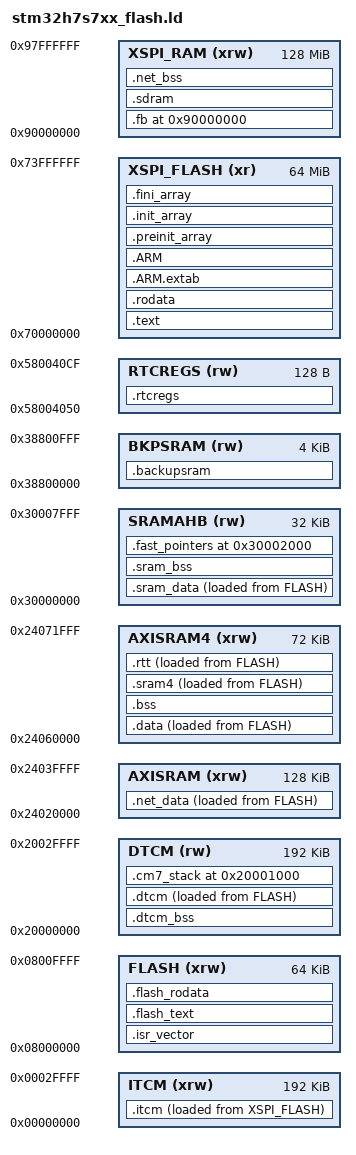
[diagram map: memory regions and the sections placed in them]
/*
******************************************************************************
**
** @file        : LinkerScript.ld
**
** @author      : Auto-generated by STM32CubeIDE
**
** @brief       : Linker script for STM32H7S7xx Device from STM32H7RS series
**                      64Kbytes FLASH
**                      456Kbytes RAM
**
**                Set heap size, stack size and stack location according
**                to application requirements.
**
**                Set memory bank area and size if external memory is used
**
**  Target      : STMicroelectronics STM32
**
**  Distribution: The file is distributed as is, without any warranty
**                of any kind.
**
******************************************************************************
** @attention
**
** Copyright (c) 2023 STMicroelectronics.
** All rights reserved.
**
** This software is licensed under terms that can be found in the LICENSE file
** in the root directory of this software component.
** If no LICENSE file comes with this software, it is provided AS-IS.
**
******************************************************************************
*/

/* Entry Point */
ENTRY(Reset_Handler)

_Min_Heap_Size = 0x200; /* required amount of heap */
_Min_Stack_Size = 0x400; /* required amount of stack */

__FLASH_BEGIN  = 0x08000000;
__FLASH_SIZE   = 0x00010000;

/* Memories definition */
MEMORY
{
  AXISRAM       (xrw) : ORIGIN = 0x24020000,    LENGTH = 0x20000
  AXISRAM4  (xrw) : ORIGIN = 0x24060000, LENGTH = 0x12000

  ITCM      (xrw) : ORIGIN = 0x00000000,    LENGTH = 0x00030000
  DTCM       (rw) : ORIGIN = 0x20000000,    LENGTH = 0x00030000
  SRAMAHB   (rw)  : ORIGIN = 0x30000000,  LENGTH = 0x00008000
  BKPSRAM   (rw)  : ORIGIN = 0x38800000,  LENGTH = 0x00001000

  FLASH     (xrw) : ORIGIN = __FLASH_BEGIN, LENGTH = __FLASH_SIZE

  XSPI_RAM  (xrw) : ORIGIN = 0x90000000, LENGTH = 0x08000000
  XSPI_FLASH (xr) : ORIGIN = 0x70000000, LENGTH = 0x04000000

  /* RTC backup registers */
  RTCREGS (rw)        : ORIGIN = 0x58004050, LENGTH = 128
}

/* Sections */
SECTIONS
{
  /* The startup code into "FLASH" Rom type memory */
  .isr_vector :
  {
    . = ALIGN(4);
    KEEP(*(.isr_vector)) /* Startup code */
    . = ALIGN(4);
  } >FLASH

  /* Startup code to bring the xspi interface online */
  .flash_text :
  {
    . = ALIGN(4);
    *(.flash_text)
    *(.flash_text*)
    *SEGGER_RTT*(.text)
    *SEGGER_RTT*(.text*)
    . = ALIGN(4);
  } >FLASH


  /* The program code and other data into "FLASH" Rom type memory */
  .text :
  {
    . = ALIGN(4);
    *(.text)           /* .text sections (code) */
    *(.text*)          /* .text* sections (code) */
    *(.glue_7)         /* glue arm to thumb code */
    *(.glue_7t)        /* glue thumb to arm code */
    *(.eh_frame)

    KEEP (*(.init))
    KEEP (*(.fini))

    . = ALIGN(4);
    _etext = .;        /* define a global symbols at end of code */
  } >XSPI_FLASH

  /* Boot-time constant data */
  .flash_rodata :
  {
    . = ALIGN(4);
    *(.flash_rodata)
    *(.flash_rodata*)
    *(.flash_string)
    *(.flash_string*)
    . = ALIGN(4);
  } >FLASH

  /* Constant data into "FLASH" Rom type memory */
  .rodata :
  {
    . = ALIGN(4);
    *(.rodata)         /* .rodata sections (constants, strings, etc.) */
    *(.rodata*)        /* .rodata* sections (constants, strings, etc.) */
    . = ALIGN(4);
  } >XSPI_FLASH

  .ARM.extab (READONLY) : /* The READONLY keyword is only supported in GCC11 and later, remove it if using GCC10 or earlier. */
  {
    . = ALIGN(4);
    *(.ARM.extab* .gnu.linkonce.armextab.*)
    . = ALIGN(4);
  } >XSPI_FLASH

  .ARM (READONLY) : /* The READONLY keyword is only supported in GCC11 and later, remove it if using GCC10 or earlier. */
   {
    . = ALIGN(4);
    __exidx_start = .;
    *(.ARM.exidx*)
    __exidx_end = .;
    . = ALIGN(4);
  } >XSPI_FLASH

  .preinit_array  (READONLY) : /* The READONLY keyword is only supported in GCC11 and later, remove it if using GCC10 or earlier. */
  {
    . = ALIGN(4);
    PROVIDE_HIDDEN (__preinit_array_start = .);
    KEEP (*(.preinit_array*))
    PROVIDE_HIDDEN (__preinit_array_end = .);
    . = ALIGN(4);
  } >XSPI_FLASH

  .init_array (READONLY) : /* The READONLY keyword is only supported in GCC11 and later, remove it if using GCC10 or earlier. */
  {
    . = ALIGN(4);
    PROVIDE_HIDDEN (__init_array_start = .);
    KEEP (*(SORT(.init_array.*)))
    KEEP (*(.init_array*))
    PROVIDE_HIDDEN (__init_array_end = .);
    . = ALIGN(4);
  } >XSPI_FLASH

  .fini_array (READONLY) : /* The READONLY keyword is only supported in GCC11 and later, remove it if using GCC10 or earlier. */
  {
    . = ALIGN(4);
    PROVIDE_HIDDEN (__fini_array_start = .);
    KEEP (*(SORT(.fini_array.*)))
    KEEP (*(.fini_array*))
    PROVIDE_HIDDEN (__fini_array_end = .);
    . = ALIGN(4);
  } >XSPI_FLASH

  /* Used by the startup to initialize data */
  _sidata = LOADADDR(.data);

  /* Initialized data sections into "RAM" Ram type memory */
  .data :
  {
    . = ALIGN(4);
    _sdata = .;        /* create a global symbol at data start */
    *(.data)           /* .data sections */
    *(.data*)          /* .data* sections */
    *(.RamFunc)        /* .RamFunc sections */
    *(.RamFunc*)       /* .RamFunc* sections */


    . = ALIGN(1K);
    _stusb_data = .;
    *(.tusb_data)
    *(.tusb_data*)
    *(.tusb_bss)
    *(.tusb_bss*)
    *libtusb.a:*(.data)
    *libtusb.a:*(.data*)
    *libtusb.a:*(.bss)
    *libtusb.a:*(.bss*)
    _etusb_data = .;

    . = ALIGN(4);
    _edata = .;        /* define a global symbol at data end */

  } >AXISRAM4 AT> FLASH

  /* Uninitialized data section into "RAM" Ram type memory */
  . = ALIGN(4);
  .bss :
  {
    /* This is used by the startup in order to initialize the .bss section */
    _sbss = .;         /* define a global symbol at bss start */
    __bss_start__ = _sbss;
    *(.bss)
    *(.bss*)
    *(COMMON)

    . = ALIGN(4);
    _ebss = .;         /* define a global symbol at bss end */
    __bss_end__ = _ebss;
  } >AXISRAM4

  . = ALIGN(4);
  .dtcm_bss (NOLOAD) :
  {
    /* This is used by the startup in order to initialize the .bss secion */
    _sdtcm_bss = .;         /* define a global symbol at bss start */
    *(.dtcm_bss)
    *(.dtcm_bss*)
    *(COMMON)

    . = ALIGN(4);
    _edtcm_bss = .;         /* define a global symbol at bss end */
  } >DTCM

  .dtcm :
  {
    . = ALIGN(4);
    _sdtcm = .;       /* create a global symbol at ccmram start */
    *(.dtcm)
    *(.dtcm*)
    
    . = ALIGN(4);
    _edtcm = .;       /* create a global symbol at ccmram end */
    *(.noinit_dtcm*)  /* for those bits we do not need to initialize */
    _edtcm2 = .;
  } >DTCM AT> FLASH
  _sdtcm_flash = LOADADDR(.dtcm);

  .itcm (NOLOAD) :
  {
    . = ALIGN(4);
    _sitcm = .;       /* create a global symbol at ccmram start */
    *(.itcm)
    *(.itcm*)
    
    . = ALIGN(4);
    _eitcm = .;       /* create a global symbol at ccmram end */
  } >ITCM AT> XSPI_FLASH
  _sitcm_flash = LOADADDR(.itcm);

  .fb 0x90000000 (NOLOAD) :
  {
    . = . + 0x400000;
  } >XSPI_RAM

  .sdram (NOLOAD) :
  {
    . = ALIGN(4);
    _ssdram = .;
    *(.sdram)
    *(.sdram*)
    . = ALIGN(4);
    _esdram = .;
  } >XSPI_RAM

  .net_data ALIGN(1 << LOG2CEIL(_elwip_data - _slwip_data)):
  {
    _slwip_data = .;
    *(.net_data)
    *(.net_data*)
    _elwip_init_data = .;
  } >AXISRAM AT> FLASH

  .net_bss (NOLOAD):
  {
    _slwip_bss_data = .;
    *(.net_bss)
    *(.net_bss*)
    _elwip_data = .;
  } >XSPI_RAM
  _slwip_flash = LOADADDR(.net_data);

  .sram4 :
  {
    _sdata4 = .;
    *(.sram4_data)
    *(.sram4_data*)
    *(.sram4_rdata)
    *(.sram4_rdata*)
    *(.sram4)
    *(.sram4*)
    *(.sdt_data)
    *(.sdt_data*)
    *(.ext4_data)
    *(.ext4_data*)
    _edata4 = .;
  } >AXISRAM4 AT> FLASH
  _ssdata4_flash = LOADADDR(.sram4);

  /* RTT - put into WT memory region */
  .rtt ALIGN(1 << LOG2CEIL(_erttd - _srtt)):
  {
    _srtt = .;
    *(.rtt)
    *(.rtt*)
    _erttd = .;
    . = ALIGN(1 << LOG2CEIL(_erttd - _srtt));
    _ertt = .;
  } >AXISRAM4 AT> FLASH
  _srtt_flash = LOADADDR(.rtt);

  /* Initial stack for CM7 */
  .cm7_stack 0x20001000 (NOLOAD)  :
  {
    _scm7_stack = .;
    . = . + 4K;
    _ecm7_stack = .;
    _estack = .;
  } >DTCM

  .sram_data :
  {
    . = ALIGN(16);
    _ssramahb = .;
    *(.sram_data)
    *(.sram_data*)
    *(.sram_rdata)
    *(.sram_rdata*)
    _esramahb = .;
  } >SRAMAHB AT> FLASH
  _ssramahb_flash = LOADADDR(.sram_data);

  .sram_bss (NOLOAD) :
  {
    /* This is used by the startup in order to initialize the .bss secion */
    _ssram_bss = .;         /* define a global symbol at bss start */
    *(.sram_bss)
    *(.sram_bss*)
    *(COMMON)

    . = ALIGN(4);
    _esram_bss = .;         /* define a global symbol at bss end */
  } >SRAMAHB

  .backupsram (NOLOAD):
  {
    _sbackupsram = .;
    *(.backupsram)
    *(.backupsram*)
    _ebackupsram = .;
  } >BKPSRAM

  .rtcregs (NOLOAD):
  {
    _srtcregs = .;
    *(.rtcregs)
    *(.rtcregs*)
    _ertcregs = .;
  } >RTCREGS


  .fast_pointers 0x30002000 (NOLOAD) :
  {
    /* fast access to TLS pointer(s) and timing bits */
    _tls_pointers = .;
    QUAD(0);
    QUAD(0);
    _cur_ms = .;
    QUAD(0);
    QUAD(0);
    toffset = .;
    QUAD(0);
    QUAD(0);
    QUAD(0);
    QUAD(0);
  } > SRAMAHB

  /* Remove information from the compiler libraries */
  /DISCARD/ :
  {
    libc.a ( * )
    libm.a ( * )
    libgcc.a ( * )
  }

  .ARM.attributes 0 : { *(.ARM.attributes) }


}
